# M0519AE_v1 register map
File version: 1.0
Registers are 32-bit, read-write, reset 0x0 unless marked. A register's access mark holds for its fields unless they carry their own. Offsets are from the block's base; [hi:lo] are bit positions; 'fields as' and 'values as' point back to an identical list.

## TMR01 — TMR Register Map
Base 0x40010000
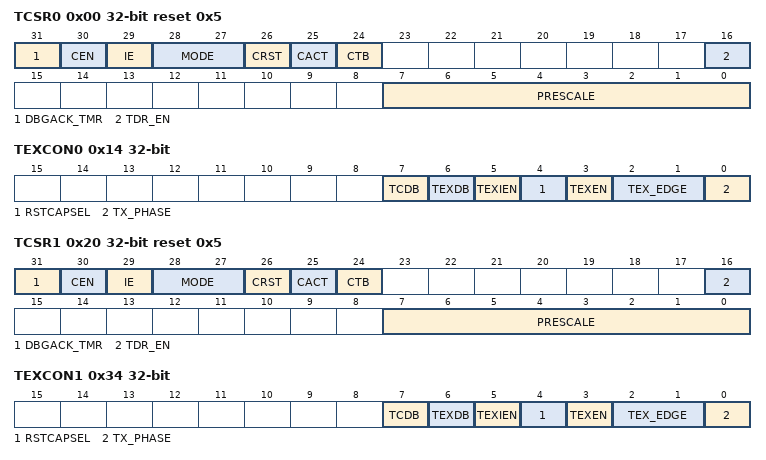
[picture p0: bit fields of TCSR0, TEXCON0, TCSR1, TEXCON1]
0x00 TCSR0 reset 0x5 — Timer0 Control and Status Register
  [31] DBGACK_TMR — ICE Debug Mode Acknowledge Disable (Write Protect). TIMER counter will keep going no matter CPU is held by ICE or not. Note: This bit is write protected. Refer to the REGWRPROT register.
    0=ICE debug mode acknowledgement effects TIMER counting; 1=ICE debug mode acknowledgement Disabled
  [30] CEN — Timer Enable Bit
    0=Stops/Suspends counting; 1=Starts counting
  [29] IE — Interrupt Enable Bit. Note: If this bit is enabled, when the timer interrupt flag TIF is set to 1, the timer interrupt signal is generated and inform to CPU.
    0=Timer Interrupt Disabled; 1=Timer Interrupt Enabled
  [28:27] MODE — Timer Counting Mode Select
    0=The Timer controller is operated in One-shot mode; 1=The Timer controller is operated in Periodic mode; 2=The Timer controller is operated in Toggle-output mode; 3=The Timer controller is operated in Continuous Counting mode
  [26] CRST — Timer Counter Reset Bit. Setting this bit will reset the 24-bit up counter value TDR and also force CEN (TCSR[30]) to 0 if CACT (TCSR[25]) is 1.
    0=No effect; 1=Reset internal 8-bit prescale counter, 24-bit up counter value and CEN bit
  [25] CACT ro — Timer Active Status Bit (Read Only). This bit indicates the up-timer status.
    0=Timer is not active; 1=Timer is active
  [24] CTB — Counter Mode Enable Bit. This bit is for external counting pin function enabled.
    0=Event counter mode Disabled; 1=Event counter mode Enabled
  [16] TDR_EN — Data Load Enable Bit. When this bit is set, timer counter value (TDR) will be updated continuously to monitor internal 24-bit up counter value as the counter is counting.
    0=Timer Data Register update Disabled; 1=Timer Data Register update Enabled while timer counter is active
  [7:0] PRESCALE — Prescale Counter
0x04 TCMPR0 — Timer0 Compare Register
  [23:0] TCMP — Timer Compared Value. TCMP is a 24-bit compared value register. When the internal 24-bit up counter value is equal to TCMP value, the TIF (TISR[0] Timer Interrupt Flag) will set to 1. Note1: Never write 0x0 or 0x1 in TCMP field, or the core will run into unknown state. Note2: When timer is operating at continuous counting mode, the 24-bit up counter will keep counting continuously even if user writes a new value into TCMP field. But if timer is operating at other modes, the 24-bit up counter will restart counting from 0 and using newest TCMP value to be the timer compared value while user writes a new value into TCMP field.
0x08 TISR0 — Timer0 Interrupt Status Register
  [0] TIF — Timer Interrupt Flag. This bit indicates the interrupt flag status of Timer while 24-bit timer up counter TDR value reaches to TCMP (TCMPR[23:0]) value. Note: This bit is cleared by writing 1 to it.
    0=No effect; 1=TDR value matches the TCMP value
0x0C TDR0 ro — Timer0 Data Register
  [23:0] TDR — Timer Data Register. If CTB (TCSR[24] ) is 0, user can read TDR value for getting current 24- bit counter value . If CTB (TCSR[24] ) is 1, user can read TDR value for getting current 24- bit event input counter value.
0x10 TCAP0 ro — Timer0 Capture Data Register
  [23:0] TCAP — Timer Capture Data Register
0x14 TEXCON0 — Timer0 External Control Register
  [7] TCDB — Timer Counter Pin De-bounce Enable Bit. Note: If this bit is enabled, the edge detection of TMx pin is detected with de-bounce circuit.
    0=TMx (x= 0~3) pin de-bounce Disabled; 1=TMx (x= 0~3) pin de-bounce Enabled
  [6] TEXDB — Timer External Capture Pin De-bounce Enable Bit. Note: If this bit is enabled, the edge detection of TMx pin is detected with de-bounce circuit.
    values as TCDB
  [5] TEXIEN — Timer External Capture Interrupt Enable Bit
    0=TMx (x= 0~3) pin detection Interrupt Disabled; 1=TMx (x= 0~3) pin detection Interrupt Enabled
  [4] RSTCAPSEL — Capture Function Selection
    0=External Capture Mode Enabled; 1=External Reset Mode Enabled
  [3] TEXEN — Timer External Capture Pin Enable Bit. This bit enables the TMx pin.
    0=TMx (x= 0~3) pin Disabled; 1=TMx (x= 0~3) pin Enabled
  [2:1] TEX_EDGE — Timer External Capture Pin Edge Detect
    0=A Falling edge on TMx (x= 0~3) pin will be detected; 1=A Rising edge on TMx (x= 0~3) pin will be detected; 2=Either Rising or Falling edge on TMx (x= 0~3) pin will be detected
  [0] TX_PHASE — Timer External Count Phase
    0=A Falling edge of external counting pin will be counted; 1=A Rising edge of external counting pin will be counted
0x18 TEXISR0 — Timer0 External Interrupt Status Register
  [0] TEXIF — Timer External Capture Interrupt Flag. This bit indicates the timer external capture interrupt flag status. Note3: There is a new incoming capture event detected before CPU clearing the TEXIF status. If the above condition occurred, the Timer will keep register TCAP unchanged and drop the new capture value.
    0=TMx (x= 0~3) pin interrupt did not occur; 1=TMx (x= 0~3) pin interrupt occurred
0x20 TCSR1 reset 0x5 — Timer1 Control and Status Register
  fields as TCSR0
0x24 TCMPR1 — Timer1 Compare Register
  fields as TCMPR0
0x28 TISR1 — Timer1 Interrupt Status Register
  fields as TISR0
0x2C TDR1 ro — Timer1 Data Register
  fields as TDR0
0x30 TCAP1 ro — Timer1 Capture Data Register
  [23:0] TCAP — Timer Capture Data Register
0x34 TEXCON1 — Timer1 External Control Register
  fields as TEXCON0
0x38 TEXISR1 — Timer1 External Interrupt Status Register
  fields as TEXISR0
